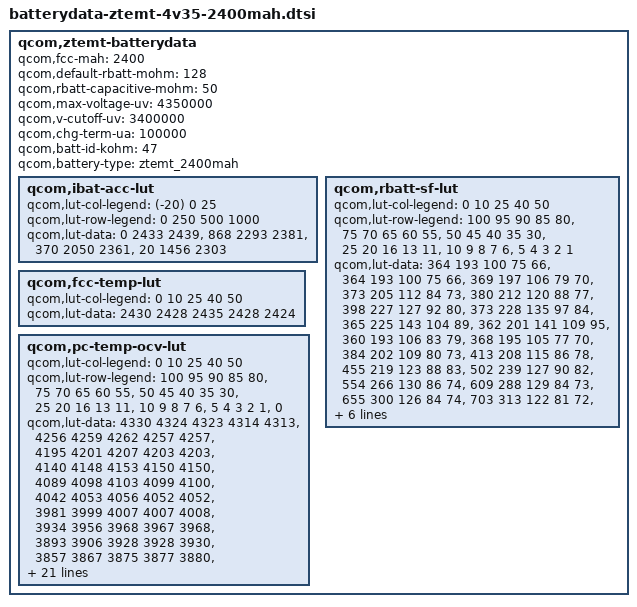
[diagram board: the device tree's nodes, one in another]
qcom,ztemt-batterydata  {
	qcom,fcc-mah = <2400>;
	qcom,default-rbatt-mohm = <128>;
	qcom,rbatt-capacitive-mohm = <50>;
	qcom,max-voltage-uv = <4350000>;
	qcom,v-cutoff-uv = <3400000>;
	qcom,chg-term-ua = <100000>;
	qcom,batt-id-kohm = <47>;
	qcom,battery-type = "ztemt_2400mah";

	qcom,ibat-acc-lut {
		qcom,lut-col-legend = <(-20) 0 25>;
		qcom,lut-row-legend = <0 250 500 1000>;
		qcom,lut-data = <0 2433 2439>,
				<868 2293 2381>,
				<370 2050 2361>,
				<20 1456 2303>;
	};

	qcom,rbatt-sf-lut {
		qcom,lut-col-legend = <0 10 25 40 50>;
		qcom,lut-row-legend = <100 95 90 85 80>,
				<75 70 65 60 55>,
				<50 45 40 35 30>,
				<25 20 16 13 11>,
				<10 9 8 7 6>,
				<5 4 3 2 1>;
		qcom,lut-data = <364 193 100 75 66>,
				<364 193 100 75 66>,
				<369 197 106 79 70>,
				<373 205 112 84 73>,
				<380 212 120 88 77>,
				<398 227 127 92 80>,
				<373 228 135 97 84>,
				<365 225 143 104 89>,
				<362 201 141 109 95>,
				<360 193 106 83 79>,
				<368 195 105 77 70>,
				<384 202 109 80 73>,
				<413 208 115 86 78>,
				<455 219 123 88 83>,
				<502 239 127 90 82>,
				<554 266 130 86 74>,
				<609 288 129 84 73>,
				<655 300 126 84 74>,
				<703 313 122 81 72>,
				<716 323 123 81 71>,
				<744 334 129 84 74>,
				<772 349 137 88 77>,
				<805 370 145 91 79>,
				<841 391 152 95 80>,
				<880 412 159 97 81>,
				<923 437 161 96 80>,
				<966 455 159 91 78>,
				<1007 474 162 95 80>,
				<1055 503 174 103 88>,
				<1122 549 200 123 106>;
	};

	qcom,fcc-temp-lut {
		qcom,lut-col-legend = <0 10 25 40 50>;
		qcom,lut-data = <2430 2428 2435 2428 2424>;
	};

	qcom,pc-temp-ocv-lut {
		qcom,lut-col-legend = <0 10 25 40 50>;
		qcom,lut-row-legend = <100 95 90 85 80>,
				<75 70 65 60 55>,
				<50 45 40 35 30>,
				<25 20 16 13 11>,
				<10 9 8 7 6>,
				<5 4 3 2 1>,
				<0>;
		qcom,lut-data = <4330 4324 4323 4314 4313>,
				<4256 4259 4262 4257 4257>,
				<4195 4201 4207 4203 4203>,
				<4140 4148 4153 4150 4150>,
				<4089 4098 4103 4099 4100>,
				<4042 4053 4056 4052 4052>,
				<3981 3999 4007 4007 4008>,
				<3934 3956 3968 3967 3968>,
				<3893 3906 3928 3928 3930>,
				<3857 3867 3875 3877 3880>,
				<3829 3838 3844 3845 3846>,
				<3806 3815 3821 3821 3822>,
				<3791 3795 3801 3802 3803>,
				<3780 3781 3785 3784 3786>,
				<3770 3771 3772 3769 3769>,
				<3757 3762 3760 3753 3747>,
				<3737 3744 3741 3732 3726>,
				<3716 3717 3713 3706 3701>,
				<3700 3697 3691 3683 3678>,
				<3692 3689 3685 3678 3673>,
				<3688 3686 3683 3677 3672>,
				<3684 3683 3682 3676 3671>,
				<3680 3681 3680 3674 3670>,
				<3676 3678 3678 3673 3668>,
				<3670 3673 3674 3669 3664>,
				<3659 3665 3663 3660 3654>,
				<3639 3641 3638 3634 3626>,
				<3607 3605 3595 3587 3584>,
				<3559 3553 3542 3535 3534>,
				<3492 3486 3477 3473 3476>,
				<3400 3400 3400 3400 3400>;
	};
};
